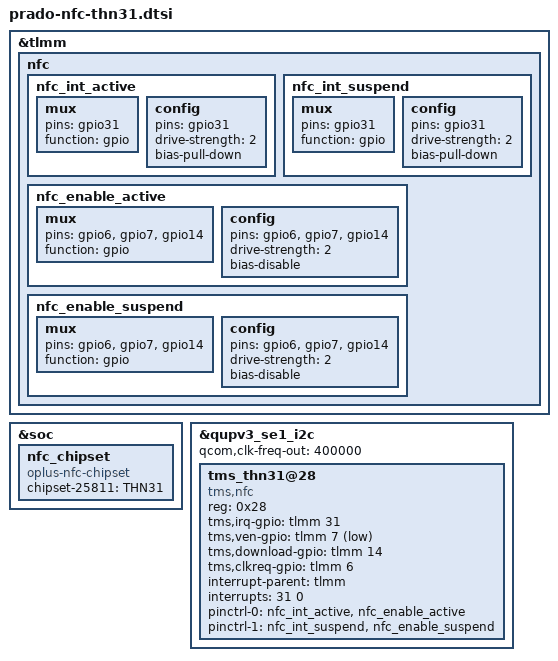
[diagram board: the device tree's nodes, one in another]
/**********************************************************************************
* Copyright (c)  2008-2020  Guangdong oplus Mobile Comm Corp., Ltd
* Description: oplus thn31 nfc dtsi
*
***********************************************************************************/
&tlmm {

    nfc {
        nfc_int_active: nfc_int_active {
            /* active state */
            mux {
                /* NFC Read Interrupt */
                pins = "gpio31";
                function = "gpio";
            };

            config {
                pins = "gpio31";
                drive-strength = <2>; /* 2 MA */
                bias-pull-down;
            };
        };

        nfc_int_suspend: nfc_int_suspend {
            /* sleep state */
            mux {
                /* NFC Read Interrupt */
                pins = "gpio31";
                function = "gpio";
            };

            config {
                pins = "gpio31";
                drive-strength = <2>; /* 2 MA */
                bias-pull-down;
            };
        };

        nfc_enable_active: nfc_enable_active {
            mux {
                /* Enable, Clock request gpios */
                pins = "gpio6", "gpio7", "gpio14";
                function = "gpio";
            };

            config {
                pins = "gpio6", "gpio7", "gpio14";
                drive-strength = <2>; /* 2 MA */
                bias-disable;
            };
        };

        nfc_enable_suspend: nfc_enable_suspend {
            mux {
                pins = "gpio6", "gpio7", "gpio14";
                function = "gpio";
            };

            config {
                pins = "gpio6", "gpio7", "gpio14";
                drive-strength = <2>; /* 2 MA */
                bias-disable;
            };
        };
    };
};


&soc {
    //add for nfc_chipset
    nfc_chipset {
        compatible = "oplus-nfc-chipset";
        chipset-25811 = "THN31";
    };
};

&qupv3_se1_i2c {
    status = "ok";
    qcom,clk-freq-out = <400000>;
    tms_thn31@28 {
        compatible = "tms,nfc";
        reg = <0x28>;
        tms,irq-gpio = <&tlmm 31 0x00>;
        tms,ven-gpio = <&tlmm 7 0x01>;
        tms,download-gpio = <&tlmm 14 0x00>;
        tms,clkreq-gpio = <&tlmm 6 0x00>;
        interrupt-parent = <&tlmm>;
        interrupts = <31 0>;
        interrupt-names = "nfc_irq";
        pinctrl-names = "nfc_active", "nfc_suspend";
        pinctrl-0 = <&nfc_int_active &nfc_enable_active>;
        pinctrl-1 = <&nfc_int_suspend &nfc_enable_suspend>;
    };
};
